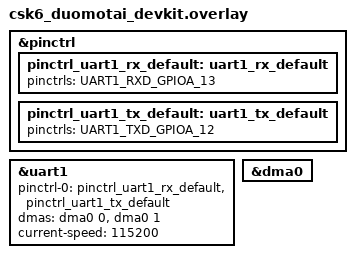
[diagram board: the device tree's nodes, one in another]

&pinctrl {
    pinctrl_uart1_rx_default: uart1_rx_default{
        pinctrls = <UART1_RXD_GPIOA_13>;
    };

    pinctrl_uart1_tx_default: uart1_tx_default{
        pinctrls = <UART1_TXD_GPIOA_12>;
    };
};

&uart1 {
    pinctrl-0 = <&pinctrl_uart1_rx_default &pinctrl_uart1_tx_default>;
    pinctrl-names = "default";
    dmas = <&dma0 0>, <&dma0 1>;
    dma-names = "tx", "rx";
    status = "okay";
    current-speed = <115200>;
};

&dma0 {
    status = "okay";
};

dut: &uart1{
    
};
